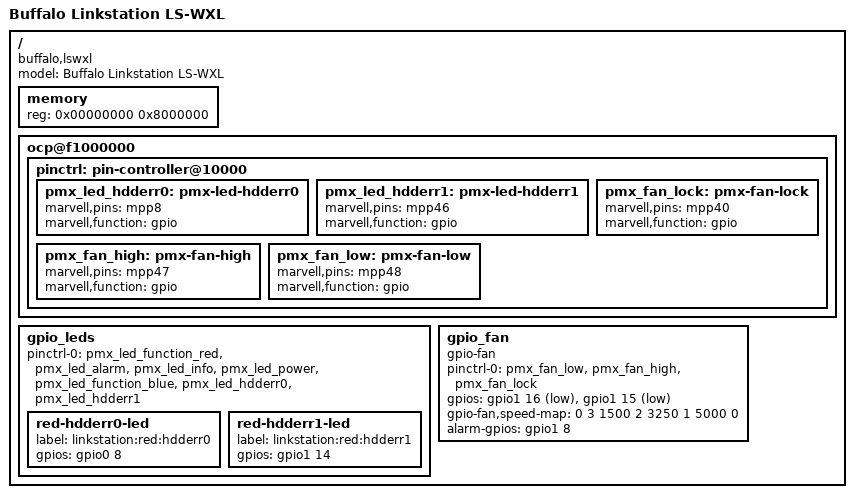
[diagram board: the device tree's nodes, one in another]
/*
 * Device Tree file for Buffalo Linkstation LS-WXL
 *
 * Copyright (C) 2015, 2016
 * Roger Shimizu <rogershimizu@gmail.com>
 *
 * This file is dual-licensed: you can use it either under the terms
 * of the GPL or the X11 license, at your option. Note that this dual
 * licensing only applies to this file, and not this project as a
 * whole.
 *
 *  a) This file is free software; you can redistribute it and/or
 *     modify it under the terms of the GNU General Public License as
 *     published by the Free Software Foundation; either version 2 of the
 *     License, or (at your option) any later version.
 *
 *     This file is distributed in the hope that it will be useful,
 *     but WITHOUT ANY WARRANTY; without even the implied warranty of
 *     MERCHANTABILITY or FITNESS FOR A PARTICULAR PURPOSE.  See the
 *     GNU General Public License for more details.
 *
 * Or, alternatively,
 *
 *  b) Permission is hereby granted, free of charge, to any person
 *     obtaining a copy of this software and associated documentation
 *     files (the "Software"), to deal in the Software without
 *     restriction, including without limitation the rights to use,
 *     copy, modify, merge, publish, distribute, sublicense, and/or
 *     sell copies of the Software, and to permit persons to whom the
 *     Software is furnished to do so, subject to the following
 *     conditions:
 *
 *     The above copyright notice and this permission notice shall be
 *     included in all copies or substantial portions of the Software.
 *
 *     THE SOFTWARE IS PROVIDED "AS IS", WITHOUT WARRANTY OF ANY KIND,
 *     EXPRESS OR IMPLIED, INCLUDING BUT NOT LIMITED TO THE WARRANTIES
 *     OF MERCHANTABILITY, FITNESS FOR A PARTICULAR PURPOSE AND
 *     NONINFRINGEMENT. IN NO EVENT SHALL THE AUTHORS OR COPYRIGHT
 *     HOLDERS BE LIABLE FOR ANY CLAIM, DAMAGES OR OTHER LIABILITY,
 *     WHETHER IN AN ACTION OF CONTRACT, TORT OR OTHERWISE, ARISING
 *     FROM, OUT OF OR IN CONNECTION WITH THE SOFTWARE OR THE USE OR
 *     OTHER DEALINGS IN THE SOFTWARE.
 */

/dts-v1/;
#include "kirkwood-linkstation-duo-6281.dtsi"

/ {
	model = "Buffalo Linkstation LS-WXL";
	compatible = "buffalo,lswxl", "marvell,kirkwood-88f6281", "marvell,kirkwood";

	memory { /* 128 MB */
		device_type = "memory";
		reg = <0x00000000 0x8000000>;
	};

	ocp@f1000000 {
		pinctrl: pin-controller@10000 {
			pmx_led_hdderr0: pmx-led-hdderr0 {
				marvell,pins = "mpp8";
				marvell,function = "gpio";
			};
			pmx_led_hdderr1: pmx-led-hdderr1 {
				marvell,pins = "mpp46";
				marvell,function = "gpio";
			};
			pmx_fan_lock: pmx-fan-lock {
				marvell,pins = "mpp40";
				marvell,function = "gpio";
			};
			pmx_fan_high: pmx-fan-high {
				marvell,pins = "mpp47";
				marvell,function = "gpio";
			};
			pmx_fan_low: pmx-fan-low {
				marvell,pins = "mpp48";
				marvell,function = "gpio";
			};
		};
	};

	gpio_leds {
		pinctrl-0 = <&pmx_led_function_red &pmx_led_alarm
			     &pmx_led_info &pmx_led_power
			     &pmx_led_function_blue
			     &pmx_led_hdderr0
			     &pmx_led_hdderr1>;

		red-hdderr0-led {
			label = "linkstation:red:hdderr0";
			gpios = <&gpio0 8 GPIO_ACTIVE_HIGH>;
		};

		red-hdderr1-led {
			label = "linkstation:red:hdderr1";
			gpios = <&gpio1 14 GPIO_ACTIVE_HIGH>;
		};
	};

	gpio_fan {
		compatible = "gpio-fan";
		pinctrl-0 = <&pmx_fan_low &pmx_fan_high &pmx_fan_lock>;
		pinctrl-names = "default";

		gpios = <&gpio1 16 GPIO_ACTIVE_LOW
			 &gpio1 15 GPIO_ACTIVE_LOW>;

		gpio-fan,speed-map = <0 3
				1500 2
				3250 1
				5000 0>;

		alarm-gpios = <&gpio1 8 GPIO_ACTIVE_HIGH>;
	};
};
